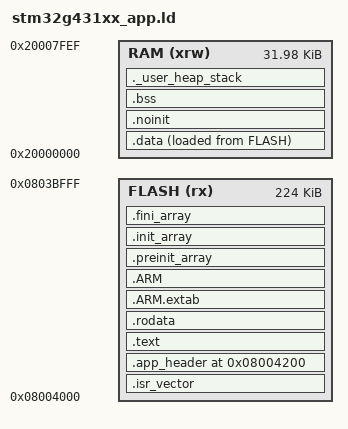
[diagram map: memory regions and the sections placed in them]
/* Application Linker Script for STM32G431xx (with Bootloader) */
/* Application: 0x08004000 - 0x0803BFFF (224KB) */

ENTRY(Reset_Handler)

_estack = ORIGIN(RAM) + LENGTH(RAM);
_Min_Heap_Size = 0x200;
_Min_Stack_Size = 0x400;

MEMORY
{
  RAM (xrw)    : ORIGIN = 0x20000000, LENGTH = 32K - 16  /* 濞ｅ洦绻勯弳鈧柡鍫亜閻?16 bytes 缂?boot flag */
  FLASH (rx)   : ORIGIN = 0x08004000, LENGTH = 224K      /* Application 闁告牕鎼悡?*/
}

PHDRS
{
  text PT_LOAD FLAGS(5);
  data PT_LOAD FLAGS(6);
}

SECTIONS
{
  /* 闁告碍鍨块崳铏规偘?*/
  .isr_vector :
  {
    . = ALIGN(4);
    KEEP(*(.isr_vector))
    . = ALIGN(4);
  } >FLASH :text

  /* App Header (濞达絽绉崇花顒勫触閹达箑娅ら悶娑栧妼閹?0x200 闁稿绻掍簺濠? */
  .app_header 0x08004200 :
  {
    KEEP(*(.app_header))
    . = ALIGN(4);
  } >FLASH :text

  .text :
  {
    . = ALIGN(4);
    *(.text)
    *(.text*)
    *(.glue_7)
    *(.glue_7t)
    *(.eh_frame)
    KEEP (*(.init))
    KEEP (*(.fini))
    . = ALIGN(4);
    _etext = .;
  } >FLASH :text

  .rodata :
  {
    . = ALIGN(4);
    *(.rodata)
    *(.rodata*)
    . = ALIGN(4);
  } >FLASH :text

  .ARM.extab   : { *(.ARM.extab* .gnu.linkonce.armextab.*) } >FLASH :text
  .ARM : {
    __exidx_start = .;
    *(.ARM.exidx*)
    __exidx_end = .;
  } >FLASH :text

  .preinit_array :
  {
    PROVIDE_HIDDEN (__preinit_array_start = .);
    KEEP (*(.preinit_array*))
    PROVIDE_HIDDEN (__preinit_array_end = .);
  } >FLASH :text

  .init_array :
  {
    PROVIDE_HIDDEN (__init_array_start = .);
    KEEP (*(SORT(.init_array.*)))
    KEEP (*(.init_array*))
    PROVIDE_HIDDEN (__init_array_end = .);
  } >FLASH :text

  .fini_array :
  {
    PROVIDE_HIDDEN (__fini_array_start = .);
    KEEP (*(SORT(.fini_array.*)))
    KEEP (*(.fini_array*))
    PROVIDE_HIDDEN (__fini_array_end = .);
  } >FLASH :text

  _sidata = LOADADDR(.data);

  .data :
  {
    . = ALIGN(4);
    _sdata = .;
    *(.data)
    *(.data*)
    . = ALIGN(4);
    _edata = .;
  } >RAM AT> FLASH :data

  /* Boot flag 闁告牕鎼悡?(濞戞挸绉撮崹鍨叏鐎ｎ亜顕ч柨娑樿嫰椤﹀弶鎷呭鍕闁? */
  .noinit (NOLOAD) :
  {
    . = ALIGN(4);
    *(.noinit)
    . = ALIGN(4);
  } >RAM :data

  . = ALIGN(4);
  .bss :
  {
    _sbss = .;
    __bss_start__ = _sbss;
    *(.bss)
    *(.bss*)
    *(COMMON)
    . = ALIGN(4);
    _ebss = .;
    __bss_end__ = _ebss;
  } >RAM :data

  ._user_heap_stack (NOLOAD) :
  {
    . = ALIGN(8);
    PROVIDE ( end = . );
    PROVIDE ( _end = . );
    . = . + _Min_Heap_Size;
    . = . + _Min_Stack_Size;
    . = ALIGN(8);
  } >RAM :NONE

  /DISCARD/ :
  {
    libc.a ( * )
    libm.a ( * )
    libgcc.a ( * )
  }

  .ARM.attributes 0 : { *(.ARM.attributes) }
}
